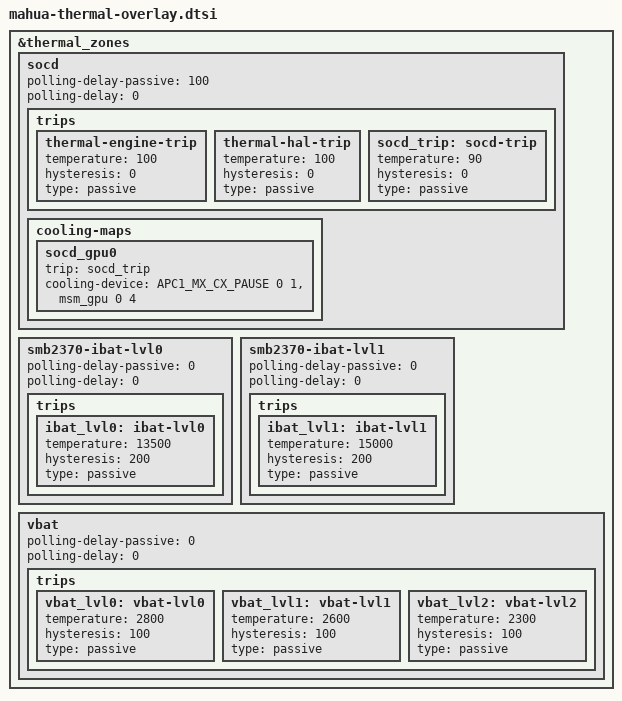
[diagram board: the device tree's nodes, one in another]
// SPDX-License-Identifier: BSD-3-Clause
/*
 * Copyright (c) Qualcomm Technologies, Inc. and/or its subsidiaries.
 */

&thermal_zones {
	socd {
		polling-delay-passive = <100>;
		polling-delay = <0>;

		trips {
			thermal-engine-trip {
				temperature = <100>;
				hysteresis = <0>;
				type = "passive";
			};

			thermal-hal-trip {
				temperature = <100>;
				hysteresis = <0>;
				type = "passive";
			};

			socd_trip: socd-trip {
				temperature = <90>;
				hysteresis = <0>;
				type = "passive";
			};
		};

		cooling-maps {
			socd_gpu0 {
				trip = <&socd_trip>;
				cooling-device = <&APC1_MX_CX_PAUSE  0 1>,
						 <&msm_gpu 0 4>;
			};
		};
	};

	smb2370-ibat-lvl0 {
		polling-delay-passive = <0>;
		polling-delay = <0>;

		trips {
			ibat_lvl0:ibat-lvl0 {
				temperature = <13500>;
				hysteresis = <200>;
				type = "passive";
			};
		};
	};

	smb2370-ibat-lvl1 {
		polling-delay-passive = <0>;
		polling-delay = <0>;

		trips {
			ibat_lvl1:ibat-lvl1 {
				temperature = <15000>;
				hysteresis = <200>;
				type = "passive";
			};
		};
	};

	vbat {
		polling-delay-passive = <0>;
		polling-delay = <0>;

		trips {
			vbat_lvl0:vbat-lvl0 {
				temperature = <2800>;
				hysteresis = <100>;
				type = "passive";
			};

			vbat_lvl1:vbat-lvl1 {
				temperature = <2600>;
				hysteresis = <100>;
				type = "passive";
			};

			vbat_lvl2:vbat-lvl2 {
				temperature = <2300>;
				hysteresis = <100>;
				type = "passive";
			};
		};
	};
};
